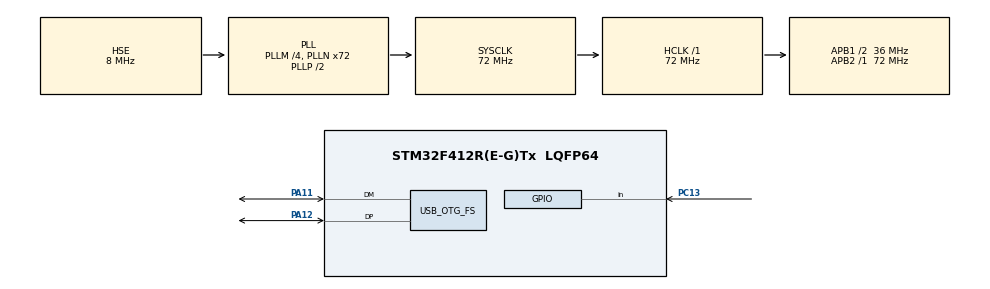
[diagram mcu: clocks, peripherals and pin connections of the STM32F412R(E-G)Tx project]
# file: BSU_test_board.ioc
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Mcu.Family=STM32F4
Mcu.Name=STM32F412R(E-G)Tx
Mcu.Package=LQFP64
NVIC.OTG_FS_IRQn=true\:0\:0\:false\:false\:true\:false\:true\:true
NVIC.PriorityGroup=NVIC_PRIORITYGROUP_4
PA11.Mode=Device_Only
PA11.Signal=USB_OTG_FS_DM
PA12.Mode=Device_Only
PA12.Signal=USB_OTG_FS_DP
PC13.Signal=GPIO_Input
PH0\ -\ OSC_IN.Mode=HSE-External-Oscillator
PH0\ -\ OSC_IN.Signal=RCC_OSC_IN
PH1\ -\ OSC_OUT.Mode=HSE-External-Oscillator
PH1\ -\ OSC_OUT.Signal=RCC_OSC_OUT
ProjectManager.HeapSize=0x200
ProjectManager.StackSize=0x400
ProjectManager.TargetToolchain=STM32CubeIDE
RCC.AHBFreq_Value=72000000
RCC.APB1CLKDivider=RCC_HCLK_DIV2
RCC.APB1Freq_Value=36000000
RCC.APB1TimFreq_Value=72000000
RCC.APB2Freq_Value=72000000
RCC.APB2TimFreq_Value=72000000
RCC.CortexFreq_Value=72000000
RCC.HCLKFreq_Value=72000000
RCC.HSE_VALUE=8000000
RCC.PLLM=4
RCC.PLLN=72
RCC.PLLQ=3
RCC.PLLSourceVirtual=RCC_PLLSOURCE_HSE
RCC.SYSCLKFreq_VALUE=72000000
RCC.SYSCLKSource=RCC_SYSCLKSOURCE_PLLCLK
RCC.USBFreq_Value=48000000
RCC.VCOOutputFreq_Value=144000000
USB_DEVICE.CLASS_NAME_FS=CDC
USB_DEVICE.VirtualMode=Cdc
USB_DEVICE.VirtualModeFS=Cdc_FS
USB_OTG_FS.VirtualMode=Device_Only
VP_USB_DEVICE_VS_USB_DEVICE_CDC_FS.Mode=CDC_FS
board=custom

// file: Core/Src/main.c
/* USER CODE BEGIN Header */
/**
  ******************************************************************************
  * @file           : main.c
  * @brief          : Main program body
  ******************************************************************************
  * @attention
  *
  * Copyright (c) 2026 STMicroelectronics.
  * All rights reserved.
  *
  * This software is licensed under terms that can be found in the LICENSE file
  * in the root directory of this software component.
  * If no LICENSE file comes with this software, it is provided AS-IS.
  *
  ******************************************************************************
  */
/* USER CODE END Header */
#include "main.h"
#include "usb_device.h"

/* USER CODE BEGIN Includes */
#include "cdc.h"
#include "bsu_protocol.h"
#include "bsu_emulator.h"
#include "bsu_backend.h"
/* USER CODE END Includes */

/* USER CODE BEGIN PD */
#define LED_GPIO_PORT  GPIOB
#define LED_GPIO_PIN   GPIO_PIN_2
/* Для этой платы кнопка на PC13 считается нажатой при уровне SET. */
#define BTN_PRESSED_LEVEL GPIO_PIN_SET
/* USER CODE END PD */

void SystemClock_Config(void);
static void MX_GPIO_Init(void);

int main(void)
{

  /* MCU Configuration--------------------------------------------------------*/

  /* Reset of all peripherals, Initializes the Flash interface and the Systick. */
  HAL_Init();

  /* Configure the system clock */
  SystemClock_Config();

  /* Initialize all configured peripherals */
  MX_GPIO_Init();
  MX_USB_DEVICE_Init();
  /* USER CODE BEGIN 2 */
  BSU_Backend_Init();
  BSU_Protocol_Init();
  BSU_Emulator_Init();
  BSU_Emulator_ApplyConfig(BSU_Backend_GetLocalConfig(), BSU_GetConfigSize());

  uint32_t led_tick = HAL_GetTick();
  uint8_t online_mode = 1u;
  GPIO_PinState btn_raw_prev = HAL_GPIO_ReadPin(GPIOC, GPIO_PIN_13);
  GPIO_PinState btn_state = btn_raw_prev;
  uint32_t btn_last_edge_ms = HAL_GetTick();
  uint32_t btn_press_start_ms = 0u;
  uint8_t long_press_done = 0u;
  uint8_t confirm_toggle_left = 0u;
  uint32_t confirm_tick = HAL_GetTick();
  /* USER CODE END 2 */

  /* Infinite loop */
  /* USER CODE BEGIN WHILE */
  while (1)
  {
    sendToCDC();

    uint32_t now = HAL_GetTick();
    GPIO_PinState btn_now = HAL_GPIO_ReadPin(GPIOC, GPIO_PIN_13);

    /* Debounce кнопки PC13 */
    if (btn_now != btn_raw_prev) {
      btn_raw_prev = btn_now;
      btn_last_edge_ms = now;
    }
    if ((now - btn_last_edge_ms) >= 40u && btn_state != btn_raw_prev) {
      btn_state = btn_raw_prev;
      if (btn_state == BTN_PRESSED_LEVEL) { /* нажатие */
        btn_press_start_ms = now;
        long_press_done = 0u;
      } else { /* отпускание */
        if (!long_press_done) {
          online_mode++;
          if (online_mode > 4u) {
            online_mode = 1u;
          }
          BSU_Emulator_SetOnlineMode(online_mode);
        }
      }
    }

    /* Удержание 5 секунд: сброс к дефолту + сохранить + подтвердить 3 быстрыми миганиями */
    if (btn_state == BTN_PRESSED_LEVEL && !long_press_done && (now - btn_press_start_ms) >= 5000u) {
      long_press_done = 1u;
      BSU_DefaultConfig();
      BSU_SaveConfig();
      online_mode = 1u;
      BSU_Emulator_SetOnlineMode(online_mode);
      confirm_toggle_left = 6u;          /* 3 мигания = 6 переключений */
      confirm_tick = now;
      HAL_GPIO_WritePin(LED_GPIO_PORT, LED_GPIO_PIN, GPIO_PIN_SET);
    }

    BSU_Emulator_Process();

    /* Индикация:
     * - при удержании кнопки до срабатывания long-press: LED не мигает;
     * - при успешном long-press: 3 быстрых мигания (период 0.3 с);
     * - иначе обычный режим 1/5 Гц. */
    if (confirm_toggle_left > 0u) {
      if ((now - confirm_tick) >= 150u) { /* 150 ms on/off => период 300 ms */
        confirm_tick = now;
        HAL_GPIO_TogglePin(LED_GPIO_PORT, LED_GPIO_PIN);
        confirm_toggle_left--;
        if (confirm_toggle_left == 0u) {
          led_tick = now;
          HAL_GPIO_WritePin(LED_GPIO_PORT, LED_GPIO_PIN, GPIO_PIN_RESET);
        }
      }
    } else if (btn_state == BTN_PRESSED_LEVEL) {
      HAL_GPIO_WritePin(LED_GPIO_PORT, LED_GPIO_PIN, GPIO_PIN_RESET);
    } else {
      uint32_t led_period_ms = 1000u; /* mode 1: все онлайн */
      if (online_mode == 2u) {
        led_period_ms = 200u;  /* mode 2: только ППКУ */
      } else if (online_mode == 3u) {
        led_period_ms = 100u;  /* mode 3: ППКУ + 2*K1 + KR (самый быстрый) */
      } else if (online_mode == 4u) {
        led_period_ms = 350u;  /* mode 4: МКУ онлайн, ППКУ молчит */
      }
      if (now - led_tick >= led_period_ms) {
        led_tick = now;
        HAL_GPIO_TogglePin(LED_GPIO_PORT, LED_GPIO_PIN);
      }
    }
    /* USER CODE END WHILE */

  }
}

void SystemClock_Config(void)
{
  RCC_OscInitTypeDef RCC_OscInitStruct = {0};
  RCC_ClkInitTypeDef RCC_ClkInitStruct = {0};

  /** Configure the main internal regulator output voltage
  */
  __HAL_RCC_PWR_CLK_ENABLE();
  __HAL_PWR_VOLTAGESCALING_CONFIG(PWR_REGULATOR_VOLTAGE_SCALE1);

  /** Initializes the RCC Oscillators according to the specified parameters
  * in the RCC_OscInitTypeDef structure.
  */
  RCC_OscInitStruct.OscillatorType = RCC_OSCILLATORTYPE_HSE;
  RCC_OscInitStruct.HSEState = RCC_HSE_ON;
  RCC_OscInitStruct.PLL.PLLState = RCC_PLL_ON;
  RCC_OscInitStruct.PLL.PLLSource = RCC_PLLSOURCE_HSE;
  RCC_OscInitStruct.PLL.PLLM = 4;
  RCC_OscInitStruct.PLL.PLLN = 72;
  RCC_OscInitStruct.PLL.PLLP = RCC_PLLP_DIV2;
  RCC_OscInitStruct.PLL.PLLQ = 3;
  RCC_OscInitStruct.PLL.PLLR = 2;
  if (HAL_RCC_OscConfig(&RCC_OscInitStruct) != HAL_OK)
  {
    Error_Handler();
  }

  /** Initializes the CPU, AHB and APB buses clocks
  */
  RCC_ClkInitStruct.ClockType = RCC_CLOCKTYPE_HCLK|RCC_CLOCKTYPE_SYSCLK
                              |RCC_CLOCKTYPE_PCLK1|RCC_CLOCKTYPE_PCLK2;
  RCC_ClkInitStruct.SYSCLKSource = RCC_SYSCLKSOURCE_PLLCLK;
  RCC_ClkInitStruct.AHBCLKDivider = RCC_SYSCLK_DIV1;
  RCC_ClkInitStruct.APB1CLKDivider = RCC_HCLK_DIV2;
  RCC_ClkInitStruct.APB2CLKDivider = RCC_HCLK_DIV1;

  if (HAL_RCC_ClockConfig(&RCC_ClkInitStruct, FLASH_LATENCY_2) != HAL_OK)
  {
    Error_Handler();
  }
}

static void MX_GPIO_Init(void)
{
  GPIO_InitTypeDef GPIO_InitStruct = {0};

  /* GPIO Ports Clock Enable */
  __HAL_RCC_GPIOC_CLK_ENABLE();
  __HAL_RCC_GPIOH_CLK_ENABLE();
  __HAL_RCC_GPIOA_CLK_ENABLE();
  __HAL_RCC_GPIOB_CLK_ENABLE();

  /*Configure GPIO pin : PC13 */
  GPIO_InitStruct.Pin = GPIO_PIN_13;
  GPIO_InitStruct.Mode = GPIO_MODE_INPUT;
  GPIO_InitStruct.Pull = GPIO_NOPULL;
  HAL_GPIO_Init(GPIOC, &GPIO_InitStruct);

  /* USER CODE BEGIN MX_GPIO_Init_2 */
  /* LED на PB2 - мигание раз в секунду */
  GPIO_InitStruct.Pin = LED_GPIO_PIN;
  GPIO_InitStruct.Mode = GPIO_MODE_OUTPUT_PP;
  GPIO_InitStruct.Pull = GPIO_NOPULL;
  GPIO_InitStruct.Speed = GPIO_SPEED_FREQ_LOW;
  HAL_GPIO_Init(LED_GPIO_PORT, &GPIO_InitStruct);
  HAL_GPIO_WritePin(LED_GPIO_PORT, LED_GPIO_PIN, GPIO_PIN_RESET);
  /* USER CODE END MX_GPIO_Init_2 */
}

void Error_Handler(void)
{
  __disable_irq();
  while (1)
  {
  }
}
